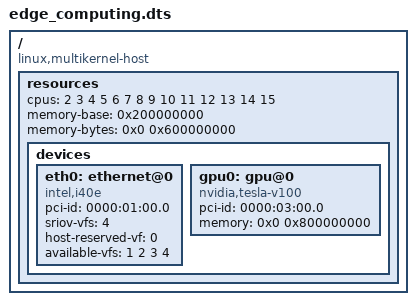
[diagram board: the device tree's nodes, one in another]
/*
 * Edge Computing Baseline Example
 *
 * Baseline defines hardware resources including GPU for edge/AI workloads.
 * Usage: kerf init --input=edge_computing.dts --apply
 */

/multikernel-v1/;

/ {
    compatible = "linux,multikernel-host";

    resources {
        cpus = <2 3 4 5 6 7 8 9 10 11 12 13 14 15>;
        memory-base = <0x200000000>;
        memory-bytes = <0x0 0x600000000>;   // 24GB
        
        devices {
            eth0: ethernet@0 {
                compatible = "intel,i40e";
                pci-id = "0000:01:00.0";
                sriov-vfs = <4>;
                host-reserved-vf = <0>;
                available-vfs = <1 2 3 4>;
            };
            
            gpu0: gpu@0 {
                compatible = "nvidia,tesla-v100";
                pci-id = "0000:03:00.0";
                memory = <0x0 0x800000000>;  // 32GB GPU memory
            };
        };
    };
};
